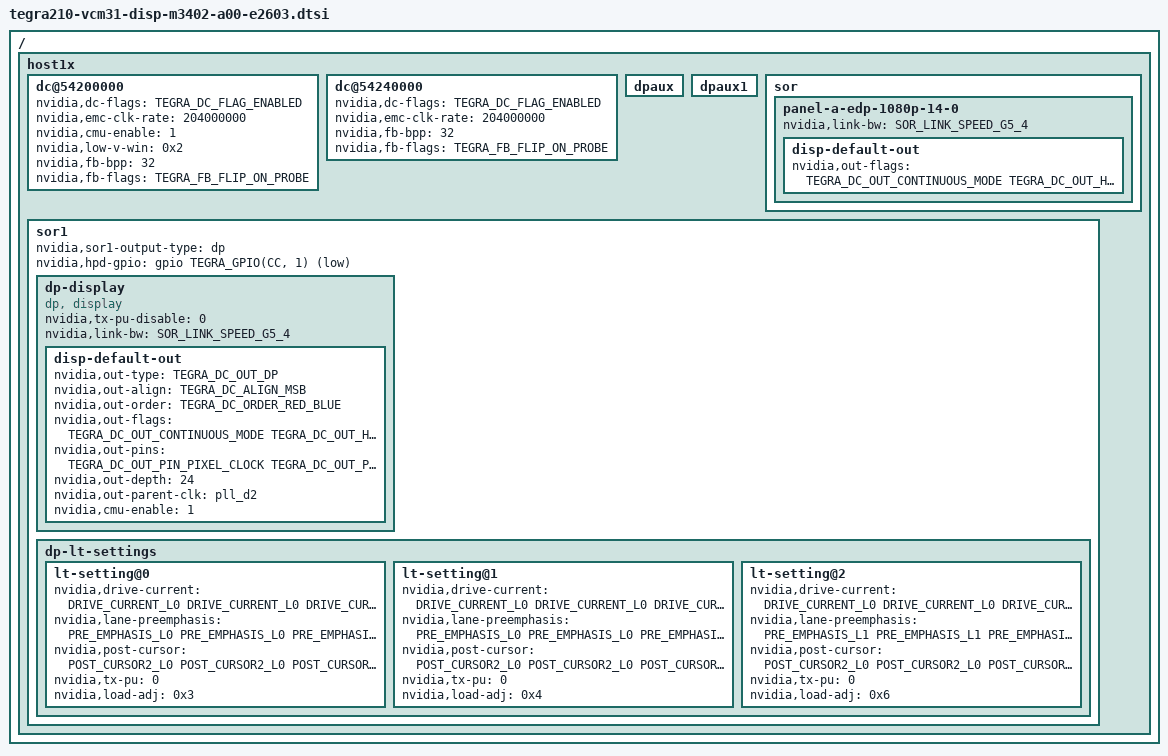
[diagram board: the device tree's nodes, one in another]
/*
 * Copyright (c) 2016, NVIDIA CORPORATION.  All rights reserved.
 *
 * This program is free software; you can redistribute it and/or modify
 * it under the terms of the GNU General Public License as published by
 * the Free Software Foundation; version 2 of the License.
 *
 * This program is distributed in the hope that it will be useful, but WITHOUT
 * ANY WARRANTY; without even the implied warranty of MERCHANTABILITY or
 * FITNESS FOR A PARTICULAR PURPOSE.  See the GNU General Public License for
 * more details.
 *
 * You should have received a copy of the GNU General Public License along
 * with this program; if not, see <http://www.gnu.org/licenses/>.
 */

#include <panel-a-edp-1080p-14-0.dtsi>
#include <dt-bindings/display/tegra-dc.h>
#include <dt-bindings/display/tegra-panel.h>

/ {
	host1x {
		/* tegradc.0 */
		dc@54200000 {
			status = "okay";
			nvidia,dc-flags = <TEGRA_DC_FLAG_ENABLED>;
			nvidia,emc-clk-rate = <204000000>;
			nvidia,cmu-enable = <1>;
			nvidia,low-v-win = <0x2>;
			nvidia,fb-bpp = <32>; /* bits per pixel */
			nvidia,fb-flags = <TEGRA_FB_FLIP_ON_PROBE>;
		};

		/* tegradc.1 */
		dc@54240000 {
			status = "okay";
			nvidia,dc-flags = <TEGRA_DC_FLAG_ENABLED>;
			nvidia,emc-clk-rate = <204000000>;
			nvidia,fb-bpp = <32>; /* bits per pixel */
			nvidia,fb-flags = <TEGRA_FB_FLIP_ON_PROBE>;
		};

		dpaux {
			status = "okay";
		};

		dpaux1 {
			status = "okay";
		};

		sor {
			status = "okay";
			panel-a-edp-1080p-14-0 {
				status = "okay";
				nvidia,link-bw = <SOR_LINK_SPEED_G5_4>;
				disp-default-out {
					nvidia,out-flags = <TEGRA_DC_OUT_CONTINUOUS_MODE TEGRA_DC_OUT_HOTPLUG_HIGH>;
                                };
			};
		};

		sor1 {
			status = "okay";
			nvidia,sor1-output-type = "dp";
			nvidia,hpd-gpio = <&gpio TEGRA_GPIO(CC, 1) 1>; /* PPC1 */
			dp-display {
				status ="okay";
				compatible = "dp, display";
				nvidia,tx-pu-disable = <0>;
				nvidia,link-bw = <SOR_LINK_SPEED_G5_4>;
				disp-default-out {
					nvidia,out-type = <TEGRA_DC_OUT_DP>;
					nvidia,out-align = <TEGRA_DC_ALIGN_MSB>;
					nvidia,out-order = <TEGRA_DC_ORDER_RED_BLUE>;
					nvidia,out-flags = <TEGRA_DC_OUT_CONTINUOUS_MODE TEGRA_DC_OUT_HOTPLUG_HIGH>;
					nvidia,out-pins = <TEGRA_DC_OUT_PIN_PIXEL_CLOCK TEGRA_DC_OUT_PIN_POL_LOW
								TEGRA_DC_OUT_PIN_DATA_ENABLE TEGRA_DC_OUT_PIN_POL_HIGH>;
					nvidia,out-depth = <24>;
					nvidia,out-parent-clk = "pll_d2";
					nvidia,cmu-enable = <1>;
				};
			};
			dp-lt-settings {
				lt-setting@0 {
					nvidia,drive-current = <DRIVE_CURRENT_L0 DRIVE_CURRENT_L0 DRIVE_CURRENT_L0 DRIVE_CURRENT_L0>;
					nvidia,lane-preemphasis = <PRE_EMPHASIS_L0 PRE_EMPHASIS_L0 PRE_EMPHASIS_L0 PRE_EMPHASIS_L0>;
					nvidia,post-cursor = <POST_CURSOR2_L0 POST_CURSOR2_L0 POST_CURSOR2_L0 POST_CURSOR2_L0>;
					nvidia,tx-pu = <0>;
					nvidia,load-adj = <0x3>;
				};
				lt-setting@1 {
					nvidia,drive-current = <DRIVE_CURRENT_L0 DRIVE_CURRENT_L0 DRIVE_CURRENT_L0 DRIVE_CURRENT_L0>;
					nvidia,lane-preemphasis = <PRE_EMPHASIS_L0 PRE_EMPHASIS_L0 PRE_EMPHASIS_L0 PRE_EMPHASIS_L0>;
					nvidia,post-cursor = <POST_CURSOR2_L0 POST_CURSOR2_L0 POST_CURSOR2_L0 POST_CURSOR2_L0>;
					nvidia,tx-pu = <0>;
					nvidia,load-adj = <0x4>;
				};
				lt-setting@2 {
						nvidia,drive-current = <DRIVE_CURRENT_L0 DRIVE_CURRENT_L0 DRIVE_CURRENT_L0 DRIVE_CURRENT_L0>;
						nvidia,lane-preemphasis = <PRE_EMPHASIS_L1 PRE_EMPHASIS_L1 PRE_EMPHASIS_L1 PRE_EMPHASIS_L1>;
						nvidia,post-cursor = <POST_CURSOR2_L0 POST_CURSOR2_L0 POST_CURSOR2_L0 POST_CURSOR2_L0>;
						nvidia,tx-pu = <0>;
						nvidia,load-adj = <0x6>;
				};
			};
		};
	};
};

